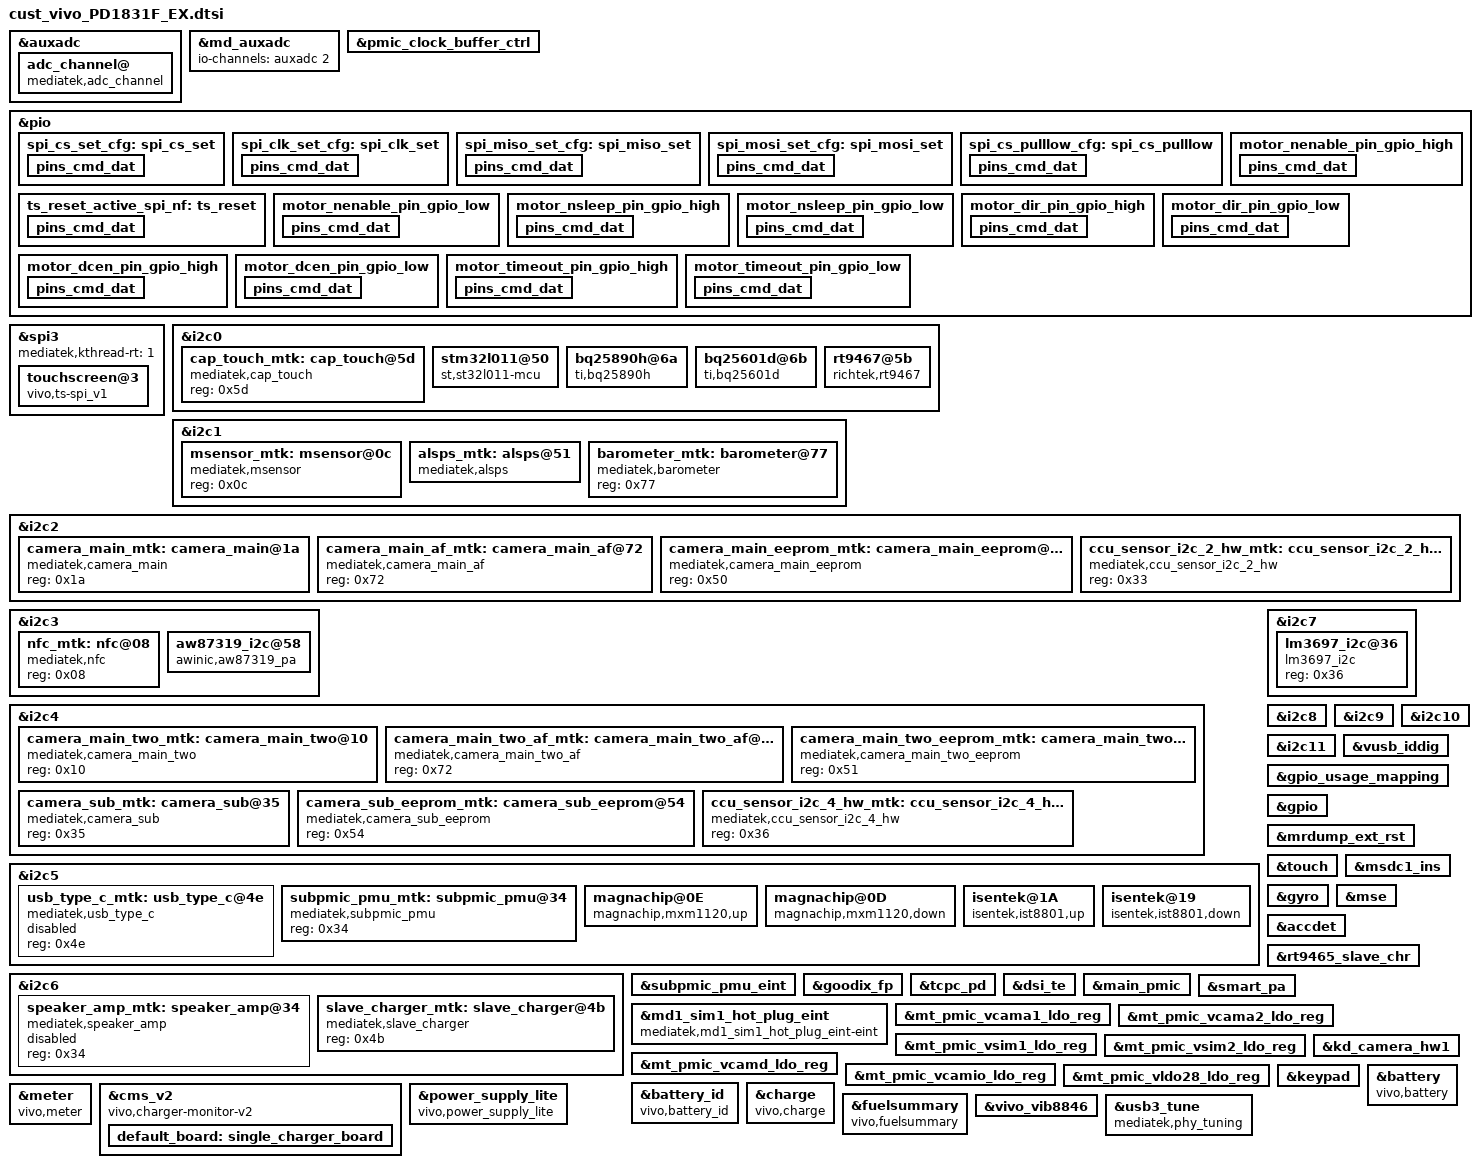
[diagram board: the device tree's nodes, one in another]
/*
 * Generated by MTK SP DrvGen Version: 3.5.160809 for MT6771.
 * 2020-12-16 15:59:14
 * Do Not Modify The File.
 * Copyright Mediatek Inc. (c) 2016.
*/

/*************************
 * ADC DTSI File
*************************/

&auxadc {
	adc_channel@ {
		compatible = "mediatek,adc_channel";
		mediatek,temperature0 = <0>;
		mediatek,temperature1 = <1>;
		mediatek,adc_fdd_rf_params_dynamic_custom_ch = <2>;
		status = "okay";
	};
};
&md_auxadc {
	io-channels = <&auxadc 2>;
};


/*************************
 * CLK_BUF DTSI File
*************************/

&pmic_clock_buffer_ctrl {
	mediatek,clkbuf-quantity = <7>;
	mediatek,clkbuf-config = <2 1 1 2 0 0 1>;
	mediatek,clkbuf-driving-current = <(-1) (-1) (-1) (-1) (-1) (-1) (-1)>;
	status = "okay";
};

&pio {
	spi_cs_set_cfg:spi_cs_set { 
		pins_cmd_dat { 
			pinmux = <PINMUX_GPIO22__FUNC_SPI3_CSB>;			
			drive-strength = <0>; 
		}; 
	}; 
	spi_clk_set_cfg:spi_clk_set { 
		pins_cmd_dat { 
			pinmux = <PINMUX_GPIO24__FUNC_SPI3_CLK>; 
			input-enable; 
			drive-strength = <0>; 
		}; 
	}; 
	spi_miso_set_cfg:spi_miso_set { 
		pins_cmd_dat { 
			pinmux = <PINMUX_GPIO21__FUNC_SPI3_MI>; 
			input-enable; 
			drive-strength = <0>; 
		}; 
	}; 
	spi_mosi_set_cfg:spi_mosi_set { 
		pins_cmd_dat { 
			pinmux = <PINMUX_GPIO23__FUNC_SPI3_MO>; 
			input-enable; 
			drive-strength = <0>; //0:2mA 1:4mA 2:2mA 3:8mA 4:10mA 5:12mA 6:14mA 7:16mA 
		}; 
	}; 
	spi_cs_pulllow_cfg:spi_cs_pulllow {
		pins_cmd_dat {
			pinmux = <PINMUX_GPIO22__FUNC_GPIO22>;
			slew-rate = <1>;
			output-low;
		};
	};
	ts_reset_active_spi_nf: ts_reset {
        pins_cmd_dat {
            pinmux = <PINMUX_GPIO171__FUNC_GPIO171>;
            slew-rate = <0>;
            bias-disable;
            output-low;
        };
    };
}; 

&spi3 {
	#address-cells = <1>;
	#size-cells = <0>;	
	mediatek,kthread-rt = <1>;
	touchscreen@3 {
		compatible = "vivo,ts-spi_v1";
		reg = <0>; //Same as CS ID
		status = "ok";
		
		pinctrl-names = "spi_cs_set", "spi_clk_set", "spi_miso_set", "spi_mosi_set", "spi_cs_pulllow", "ts_reset";
		pinctrl-0 = <&spi_cs_set_cfg>;
		pinctrl-1 = <&spi_clk_set_cfg>;
		pinctrl-2 = <&spi_miso_set_cfg>;
		pinctrl-3 = <&spi_mosi_set_cfg>;
		pinctrl-4 = <&spi_cs_pulllow_cfg>;
		pinctrl-5 = <&ts_reset_active_spi_nf>;
		

		spi-max-frequency = <9600000>;	//4800000,9600000,15000000,19200000
		
		//novatek dtsi
		//novatek,reset-gpio = <&pio 2 0x00>;
		novatek,irq-gpio = <&pio 1 0x02>;
		//novatek,clk-gpio = <&pio 24 0x00>;
		//novatek,cs-gpio = <&pio 22 0x00>;				
		
		//clock-names = "iface_clk", "core_clk";
		//clocks = <&clock_gcc clk_gcc_blsp1_ahb_clk>,
		//	<&clock_gcc clk_gcc_blsp1_qup1_spi_apps_clk>;
		/* 672 */
		//novatek,swrst-n8-addr = <0x01F01A>;

		/* 672A */
		novatek,swrst-n8-addr = <0x03F0FE>;	
		
		//synaptics dtsi
		synaptics,irq-gpio = <&pio 1 0x00>;
		synaptics,spi-mode = <3>;
		synaptics,ubl-max-freq = <6000000>;
		synaptics,ubl-byte-delay-us = <20>;

		synaptics,reset-gpio = <&pio 171 0x00>;
		synaptics,attn_polarity = <0x02>;

		synaptics,power-on-state = <1>;

		synaptics,irq-on-state = <0>;
		//synaptics,power-delay-ms = <200>;
		synaptics,reset-delay-ms = <120>;
		synaptics,reset-on-state = <0>;
		synaptics,reset-active-ms = <1>;

		// FT8719
		focaltech,reset-gpio = <&pio 171 0x00>;
		focaltech,irq-gpio = <&pio 1 0x02>;
		focaltech,max-touch-number = <10>;
		focaltech,display-coords = <0 0 1080 2340>;
		focaltech,spi-max-frequency = <8000000>;
	};	
};


/*************************
 * I2C DTSI File
*************************/

&i2c0 {
	#address-cells = <1>;
	#size-cells = <0>;
	clock-frequency = <400000>;
	mediatek,use-open-drain;
	cap_touch_mtk:cap_touch@5d {
		compatible = "mediatek,cap_touch";
		reg = <0x5d>;
		status = "okay";
	};

};

&i2c1 {
	#address-cells = <1>;
	#size-cells = <0>;
	clock-frequency = <400000>;
	mediatek,use-open-drain;
	msensor_mtk:msensor@0c {
		compatible = "mediatek,msensor";
		reg = <0x0c>;
		status = "okay";
	};

	alsps_mtk:alsps@51 {
		compatible = "mediatek,alsps";
		reg = <0x51>;
		status = "okay";
	};

	barometer_mtk:barometer@77 {
		compatible = "mediatek,barometer";
		reg = <0x77>;
		status = "okay";
	};

};

&i2c2 {
	#address-cells = <1>;
	#size-cells = <0>;
	clock-frequency = <400000>;
	mediatek,use-open-drain;
	camera_main_mtk:camera_main@1a {
		compatible = "mediatek,camera_main";
		reg = <0x1a>;
		status = "okay";
	};

	camera_main_af_mtk:camera_main_af@72 {
		compatible = "mediatek,camera_main_af";
		reg = <0x72>;
		status = "okay";
	};

	camera_main_eeprom_mtk:camera_main_eeprom@50 {
		compatible = "mediatek,camera_main_eeprom";
		reg = <0x50>;
		status = "okay";
	};

	ccu_sensor_i2c_2_hw_mtk:ccu_sensor_i2c_2_hw@33 {
		compatible = "mediatek,ccu_sensor_i2c_2_hw";
		reg = <0x33>;
		status = "okay";
	};

};

&i2c3 {
	#address-cells = <1>;
	#size-cells = <0>;
	clock-frequency = <400000>;
	mediatek,use-open-drain;
	nfc_mtk:nfc@08 {
		compatible = "mediatek,nfc";
		reg = <0x08>;
		status = "okay";
	};

};

&i2c3{
		aw87319_i2c@58 {
			compatible = "awinic,aw87319_pa";
			reg = <0x58>;
			awinic,ext_pa_spk_aw87319_rst = <&pio 153 0>;
		};
};

&i2c4 {
	#address-cells = <1>;
	#size-cells = <0>;
	clock-frequency = <400000>;
	mediatek,use-open-drain;
	camera_main_two_mtk:camera_main_two@10 {
		compatible = "mediatek,camera_main_two";
		reg = <0x10>;
		status = "okay";
	};

	camera_main_two_af_mtk:camera_main_two_af@72 {
		compatible = "mediatek,camera_main_two_af";
		reg = <0x72>;
		status = "okay";
	};

	camera_main_two_eeprom_mtk:camera_main_two_eeprom@51 {
		compatible = "mediatek,camera_main_two_eeprom";
		reg = <0x51>;
		status = "okay";
	};

	camera_sub_mtk:camera_sub@35 {
		compatible = "mediatek,camera_sub";
		reg = <0x35>;
		status = "okay";
	};

	camera_sub_eeprom_mtk:camera_sub_eeprom@54 {
		compatible = "mediatek,camera_sub_eeprom";
		reg = <0x54>;
		status = "okay";
	};

	ccu_sensor_i2c_4_hw_mtk:ccu_sensor_i2c_4_hw@36 {
		compatible = "mediatek,ccu_sensor_i2c_4_hw";
		reg = <0x36>;
		status = "okay";
	};

};

&i2c5 {
	#address-cells = <1>;
	#size-cells = <0>;
	clock-frequency = <400000>;
	mediatek,use-push-pull;
	usb_type_c_mtk:usb_type_c@4e {
		compatible = "mediatek,usb_type_c";
		reg = <0x4e>;
		status = "disable";
	};

	subpmic_pmu_mtk:subpmic_pmu@34 {
		compatible = "mediatek,subpmic_pmu";
		reg = <0x34>;
		status = "okay";
	};

};

&i2c6 {
	#address-cells = <1>;
	#size-cells = <0>;
	clock-frequency = <400000>;
	mediatek,use-open-drain;
	speaker_amp_mtk:speaker_amp@34 {
		compatible = "mediatek,speaker_amp";
		reg = <0x34>;
		status = "disabled";
	};

	slave_charger_mtk:slave_charger@4b {
		compatible = "mediatek,slave_charger";
		reg = <0x4b>;
		status = "okay";
	};

};

&i2c7 {
	#address-cells = <1>;
	#size-cells = <0>;
	clock-frequency = <400000>;
	mediatek,use-open-drain;
	lm3697_i2c@36 {
		compatible = "lm3697_i2c";
		reg = <0x36>;
		status = "okay";
	};

};

&i2c8 {
	#address-cells = <1>;
	#size-cells = <0>;
	clock-frequency = <400000>;
	mediatek,use-open-drain;
};

&i2c9 {
	#address-cells = <1>;
	#size-cells = <0>;
	clock-frequency = <400000>;
	mediatek,use-open-drain;
};

&i2c10 {
	#address-cells = <1>;
	#size-cells = <0>;
	clock-frequency = <400000>;
	mediatek,use-open-drain;
};

&i2c11 {
	#address-cells = <1>;
	#size-cells = <0>;
	clock-frequency = <400000>;
	mediatek,use-open-drain;
};

&vusb_iddig {
	interrupt-parent = <&pio>;
	interrupts = <41 IRQ_TYPE_EDGE_FALLING 41 0>;
	id-gpio = <&pio 41 0>;
	id-debounce = <50>;
	id-pu-debounce = <20>;
	id-pu-times = <5>;
};

/*************************
 * GPIO DTSI File
*************************/

&gpio_usage_mapping {
	GPIO_SIM2_SIO = <&pio 35 0>;
	GPIO_SIM2_SRST = <&pio 36 0>;
	GPIO_SIM2_SCLK = <&pio 37 0>;
	GPIO_SIM1_SCLK = <&pio 38 0>;
	GPIO_SIM1_SRST = <&pio 39 0>;
	GPIO_SIM1_SIO = <&pio 40 0>;
	/*GPIO_SIM2_HOT_PLUG = <&pio 46 0>;*/
	GPIO_SIM1_HOT_PLUG = <&pio 47 0>;
	GPIO_FDD_BAND_SUPPORT_DETECT_1ST_PIN = <&pio 72 0>;
	GPIO_FDD_BAND_SUPPORT_DETECT_2ND_PIN = <&pio 78 0>;
	GPIO_FDD_BAND_SUPPORT_DETECT_3RD_PIN = <&pio 174 0>;
	GPIO_FDD_BAND_SUPPORT_DETECT_4TH_PIN = <&pio 172 0>;
};

&gpio{
	gpio_init_default = <0 0 0 0 1 1 1>,
		<1 0 0 0 1 1 1>,
		<2 0 1 0 0 0 1>,
		<3 0 0 0 1 1 1>,
		<4 0 0 0 1 0 0>,
		<5 0 0 0 1 0 0>,
		<6 0 0 0 1 1 0>,
		<7 0 0 0 1 1 0>,
		<8 7 0 0 1 1 0>,
		<9 0 0 0 1 1 0>,
		<10 0 0 0 1 1 0>,
		<11 3 0 0 1 1 0>,
		<12 3 0 0 1 1 0>,
		<13 2 0 0 1 0 0>,
		<14 2 1 0 0 0 0>,
		<15 2 1 0 1 0 0>,
		<16 2 1 0 0 0 0>,
		<17 0 1 0 1 0 0>,
		<18 0 0 1 1 0 0>,
		<19 0 1 0 0 0 0>,
		<20 0 0 0 1 0 0>,
		<21 2 0 0 1 1 0>,
		<22 2 1 0 0 0 0>,
		<23 2 1 0 0 0 0>,
		<24 2 1 0 0 0 0>,
		<25 5 0 0 1 0 0>,
		<26 5 0 0 1 0 0>,
		<27 3 0 0 0 0 0>,
		<28 3 0 0 0 0 0>,
		<29 1 1 0 0 0 0>,
		<30 1 0 0 1 1 0>,
		<31 1 0 0 1 1 0>,
		<32 1 0 0 1 1 0>,
		<33 1 0 0 1 1 0>,
		<34 1 0 0 1 1 0>,
		<35 1 0 0 1 1 0>,
		<36 1 1 0 0 0 0>,
		<37 1 1 0 0 0 0>,
		<38 1 1 0 0 0 0>,
		<39 1 1 0 0 0 0>,
		<40 1 0 0 1 1 0>,
		<41 0 0 0 1 1 0>,
		<42 0 1 0 0 0 0>,
		<43 1 1 0 0 0 0>,
		<44 1 0 0 1 0 0>,
		<45 0 1 0 0 0 0>,
		<46 0 0 0 0 0 0>,
		<47 1 0 0 0 0 0>,
		<48 1 0 0 1 1 0>,
		<49 1 0 0 1 1 0>,
		<50 1 0 0 1 1 0>,
		<51 1 0 0 1 1 0>,
		<52 1 1 0 1 0 0>,
		<53 1 1 0 1 0 0>,
		<54 1 1 0 1 0 0>,
		<55 1 1 0 1 0 0>,
		<56 1 1 0 1 0 0>,
		<57 1 1 0 1 0 0>,
		<58 0 0 0 1 0 0>,
		<59 1 0 0 1 0 0>,
		<60 1 0 0 1 0 0>,
		<61 1 0 0 1 0 0>,
		<62 1 0 0 1 0 0>,
		<63 1 0 0 1 0 0>,
		<64 1 0 0 1 0 0>,
		<65 1 0 0 1 0 0>,
		<66 1 0 0 1 0 0>,
		<67 1 0 0 1 0 0>,
		<68 1 0 0 1 0 0>,
		<69 1 1 0 1 0 0>,
		<70 1 1 0 1 0 0>,
		<71 1 1 0 1 0 0>,
		<72 0 0 0 1 1 0>,
		<73 1 1 0 1 0 0>,
		<74 1 1 0 1 0 0>,
		<75 1 1 0 1 0 0>,
		<76 1 1 0 1 0 0>,
		<77 1 1 0 1 0 0>,
		<78 0 0 0 1 1 0>,
		<79 1 0 0 1 0 0>,
		<80 1 0 0 1 0 0>,
		<81 1 0 0 1 1 0>,
		<82 1 0 0 1 1 0>,
		<83 1 0 0 1 1 0>,
		<84 1 0 0 1 1 0>,
		<85 7 1 0 0 0 0>,
		<86 7 0 0 1 0 0>,
		<87 7 0 0 1 0 0>,
		<88 7 0 0 1 0 0>,
		<89 1 0 0 1 0 0>,
		<90 0 0 0 1 1 0>,
		<91 0 1 0 0 0 0>,
		<92 1 1 0 1 0 0>,
		<93 1 0 0 1 1 0>,
		<94 1 0 0 1 1 0>,
		<95 1 0 0 1 1 0>,
		<96 1 1 0 0 0 0>,
		<97 0 1 0 0 0 0>,
		<98 0 1 0 0 0 0>,
		<99 0 1 0 0 0 0>,
		<100 0 1 0 0 0 0>,
		<101 0 1 1 0 0 0>,
		<102 0 1 1 0 0 0>,
		<103 1 0 0 0 0 0>,
		<104 1 0 0 0 0 0>,
		<105 1 0 0 0 0 0>,
		<106 1 0 0 0 0 0>,
		<107 0 1 0 0 0 0>,
		<108 0 1 0 0 0 0>,
		<109 0 1 1 0 0 0>,
		<110 7 0 0 1 1 0>,
		<111 0 0 0 0 0 0>,
		<112 7 1 0 0 0 0>,
		<113 0 0 0 1 0 0>,
		<114 0 0 0 1 0 0>,
		<115 0 0 0 1 0 0>,
		<116 0 0 0 1 0 0>,
		<117 0 0 0 1 0 0>,
		<118 0 0 0 1 0 0>,
		<119 0 0 0 1 0 0>,
		<120 0 0 0 1 0 0>,
		<121 0 0 0 1 0 0>,
		<122 1 0 0 1 1 0>,
		<123 1 0 0 1 1 0>,
		<124 1 1 0 0 0 0>,
		<125 1 0 0 1 1 0>,
		<126 1 0 0 1 1 0>,
		<127 1 0 0 1 1 0>,
		<128 1 0 0 1 1 0>,
		<129 1 0 0 1 1 0>,
		<130 1 0 0 1 1 0>,
		<131 1 0 0 1 0 0>,
		<132 1 0 0 1 1 0>,
		<133 1 1 1 0 0 0>,
		<134 1 0 0 1 0 1>,
		<135 1 1 0 0 0 0>,
		<136 1 1 0 1 0 0>,
		<137 1 1 0 1 0 0>,
		<138 1 1 0 0 0 0>,
		<139 1 1 0 1 0 0>,
		<140 1 0 0 0 0 0>,
		<141 1 0 0 0 0 0>,
		<142 1 0 0 0 0 0>,
		<143 1 0 0 0 0 0>,
		<144 1 0 0 1 0 0>,
		<145 1 1 1 0 0 0>,
		<146 1 0 0 1 0 0>,
		<147 1 1 0 0 0 0>,
		<148 1 1 0 0 0 0>,
		<149 1 1 0 0 0 0>,
		<150 0 1 0 0 0 0>,
		<151 0 1 0 0 0 0>,
		<152 0 1 0 0 0 0>,
		<153 0 1 0 0 0 0>,
		<154 1 1 0 0 0 0>,
		<155 1 0 0 1 0 0>,
		<156 4 0 0 1 1 0>,
		<157 0 0 0 1 0 0>,
		<158 0 0 0 1 1 0>,
		<159 0 0 0 1 1 0>,
		<160 0 0 0 1 1 0>,
		<161 2 0 0 1 0 0>,
		<162 2 1 1 0 0 0>,
		<163 2 1 0 0 0 0>,
		<164 2 1 0 0 0 0>,
		<165 1 1 1 0 0 0>,
		<166 0 1 0 0 0 0>,
		<167 1 1 0 1 0 0>,
		<168 1 1 0 1 0 0>,
		<169 0 1 0 0 0 0>,
		<170 3 0 0 0 0 0>,
		<171 0 1 0 0 0 0>,
		<172 0 0 0 1 1 0>,
		<173 0 0 0 1 1 0>,
		<174 0 0 0 1 1 0>,
		<175 0 0 0 1 0 0>,
		<176 0 0 0 1 0 0>,
		<177 0 1 0 0 0 0>,
		<178 0 0 0 1 0 0>,
		<179 0 1 0 0 0 0>,
		<180 0 0 0 1 0 0>,
		<181 0 0 0 1 0 0>,
		<182 0 0 0 1 0 0>,
		<183 0 0 0 1 0 0>,
		<184 0 0 0 1 0 0>,
		<185 0 0 0 1 0 0>,
		<186 0 0 0 1 0 0>,
		<187 0 0 0 1 0 0>,
		<188 0 0 0 1 0 0>,
		<189 0 0 0 1 0 0>,
		<190 0 0 0 1 0 0>,
		<191 0 0 0 1 0 0>;
};


/*************************
 * EINT DTSI File
*************************/

#include <dt-bindings/interrupt-controller/irq.h>
#include <dt-bindings/interrupt-controller/arm-gic.h>

&mrdump_ext_rst {
	interrupt-parent = <&pio>;
	interrupts = <0 IRQ_TYPE_LEVEL_LOW 0 0>;
	deb-gpios = <&pio 0 0>;
	debounce = <512000>;
	status = "okay";
};

&touch {
	interrupt-parent = <&pio>;
	interrupts = <1 IRQ_TYPE_EDGE_FALLING 1 0>;
	status = "okay";
};

&msdc1_ins {
	interrupt-parent = <&pio>;
	interrupts = <3 IRQ_TYPE_LEVEL_LOW 3 0>;
	deb-gpios = <&pio 3 0>;
	debounce = <256000>;
	status = "okay";
};

&gyro {
	interrupt-parent = <&pio>;
	interrupts = <4 IRQ_TYPE_LEVEL_LOW 4 0>;
	status = "okay";
};

&mse {
	interrupt-parent = <&pio>;
	interrupts = <5 IRQ_TYPE_LEVEL_HIGH 5 0>;
	status = "okay";
};

&alsps_mtk {
	interrupt-parent = <&pio>;
	interrupts = <6 IRQ_TYPE_LEVEL_LOW 6 0>;
	status = "okay";
};

&accdet {
	interrupt-parent = <&pio>;
	interrupts = <8 IRQ_TYPE_LEVEL_LOW 8 0>;
	deb-gpios = <&pio 8 0>;
	debounce = <256000>;
	status = "okay";
};

&rt9465_slave_chr {
	interrupt-parent = <&pio>;
	interrupts = <9 IRQ_TYPE_LEVEL_LOW 9 0>;
	status = "okay";
};

&subpmic_pmu_eint {
	interrupt-parent = <&pio>;
	interrupts = <10 IRQ_TYPE_LEVEL_LOW 10 0>;
	status = "okay";
};

&goodix_fp {
	interrupt-parent = <&pio>;
	interrupts = <5 IRQ_TYPE_EDGE_RISING 5 0>;
	status = "okay";
};

&tcpc_pd {
	interrupt-parent = <&pio>;
	interrupts = <41 IRQ_TYPE_LEVEL_LOW 41 0>;
	status = "okay";
};

&dsi_te {
	interrupt-parent = <&pio>;
	interrupts = <44 IRQ_TYPE_EDGE_RISING 44 1>;
	status = "okay";
};

&main_pmic {
	interrupt-parent = <&pio>;
	interrupts = <182 IRQ_TYPE_LEVEL_HIGH 190 0>;
	status = "okay";
};

&smart_pa {
	interrupt-parent = <&pio>;
	interrupts = <186 IRQ_TYPE_LEVEL_LOW 173 0>;
	status = "okay";
};



/*************************
 * MD1_EINT DTSI File
*************************/

&md1_sim1_hot_plug_eint {
	compatible = "mediatek,md1_sim1_hot_plug_eint-eint";
	interrupts = <0 8>;
	debounce = <0 100000>;
	dedicated = <0 0>;
	src_pin = <0 1>;
	sockettype = <0 0>;
	status = "okay";
};

/*
&md1_sim2_hot_plug_eint {
	compatible = "mediatek,md1_sim2_hot_plug_eint-eint";
	interrupts = <1 4>;
	debounce = <1 100000>;
	dedicated = <1 0>;
	src_pin = <1 2>;
	sockettype = <1 0>;
	status = "okay";
};
*/


/*************************
 * PMIC DTSI File
*************************/

&mt_pmic_vcama1_ldo_reg {
	regulator-name = "vcama1";
	regulator-default-on = <1>; /* 0:skip, 1: off, 2:on */
	status = "okay";
};
&mt_pmic_vcama2_ldo_reg {
	regulator-name = "vcama2";
	regulator-default-on = <1>; /* 0:skip, 1: off, 2:on */
	status = "okay";
};
&mt_pmic_vsim1_ldo_reg {
	regulator-name = "vsim1";
	regulator-default-on = <1>; /* 0:skip, 1: off, 2:on */
	status = "okay";
};
&mt_pmic_vsim2_ldo_reg {
	regulator-name = "vsim2";
	regulator-default-on = <1>; /* 0:skip, 1: off, 2:on */
	status = "okay";
};
&mt_pmic_vcamd_ldo_reg {
	regulator-name = "vcamd";
	regulator-default-on = <1>; /* 0:skip, 1: off, 2:on */
	status = "okay";
};
&mt_pmic_vcamio_ldo_reg {
	regulator-name = "vcamio";
	regulator-default-on = <1>; /* 0:skip, 1: off, 2:on */
	status = "okay";
};
&mt_pmic_vldo28_ldo_reg {
	regulator-name = "vldo28";
	regulator-default-on = <1>; /* 0:skip, 1: off, 2:on */
	status = "okay";
};

&kd_camera_hw1 {
	vcama_sub-supply = <&mt_pmic_vcama1_ldo_reg>;
	vcama-supply = <&mt_pmic_vcama2_ldo_reg>;
	vcamd_sub-supply = <&mt_pmic_vcamd_ldo_reg>;
	vcamio-supply = <&mt_pmic_vcamio_ldo_reg>;
	vcamio_sub-supply = <&mt_pmic_vcamio_ldo_reg>;
	vcamio_main2-supply = <&mt_pmic_vcamio_ldo_reg>;
	vcamaf-supply = <&mt_pmic_vldo28_ldo_reg>;
	vcamaf_sub-supply = <&mt_pmic_vldo28_ldo_reg>;
	vcamaf_main2-supply = <&mt_pmic_vldo28_ldo_reg>;
	status = "okay";
};

&touch {
	vtouch-supply = <&mt_pmic_vldo28_ldo_reg>;
	status = "okay";
};


/*************************
 * POWER DTSI File
*************************/



/*************************
 * KPD DTSI File
*************************/

&keypad {
	mediatek,kpd-key-debounce = <1024>;
	mediatek,kpd-sw-pwrkey = <116>;
	mediatek,kpd-hw-pwrkey = <8>;
	mediatek,kpd-sw-rstkey  = <114>;
	mediatek,kpd-hw-rstkey = <17>;
	mediatek,kpd-use-extend-type = <0>;
	/*HW Keycode [0~71] -> Linux Keycode*/
	mediatek,kpd-hw-map-num = <72>;
	mediatek,kpd-hw-init-map = <115 0 600 0 0 0 0 0 0 0 0 0 0 0 0 0 0 0 0 0 0 0 0 0 0 0 0 0 0 0 0 0 0 0 0 0 0 0 0 0 0 0 0 0 0 0 0 0 0 0 0 0 0 0 0 0 0 0 0 0 0 0 0 0 0 0 0 0 0 0 0 0 >;
	mediatek,kpd-pwrkey-eint-gpio = <0>;
	mediatek,kpd-pwkey-gpio-din  = <0>;
	mediatek,kpd-hw-dl-key0 = <17>;
	mediatek,kpd-hw-dl-key1 = <0>;
	mediatek,kpd-hw-dl-key2 = <8>;
	mediatek,kpd-hw-recovery-key = <17>;
	mediatek,kpd-hw-factory-key = <0>;
	status = "okay";
};

/* fuxi add for battery&charge start */
&battery_id {
	status = "okay";
	compatible = "vivo,battery_id";

	vivo,bat-adc-ctrl-gpio = <&pio 166 0>;

	io-channels = <&auxadc 3>;
	io-channel-names = "battery_id_adc";

	vivo,bat-name = "B-G2 ATL 4000","B-G6 ATL 3940","B-G2 SX 4000","B-G2 ATL 4000", "UNKOWN", "UNKOWN";
};

&battery {
	status = "okay";
	compatible = "vivo,battery";

	io-channels = <&auxadc 0>,
		<&auxadc 1>,
		<&auxadc 2>;
	io-channel-names = "primary_board_therm",
		"pa_therm",
		"parallel_board_therm";

	vivo,low-volt-threshold = <3400>;
	vivo,soft-rise-percent = <92>;
	vivo,soft-rise-cumulative = <10>;
	vivo,soft-rise-keep-cumulative = <14>;
	vivo,percnet-sync-delta = <4>;
	vivo,percnet-sync-cumulative = <9>;
	vivo,full-sync-cumulative = <3>;
	vivo,soft-term-percent = <99>;
	vivo,soft-term-cumulative = <48>;
};

&charge {
	status = "okay";
	compatible = "vivo,charge";

	vivo,chg-wdt-s = <40>;
	vivo,re-chg-voltage-mv = <100>;
	vivo,prechg-voltage-mv = <3000>;
	vivo,iprechg-current-ma = <300>;
	vivo,iterm-current-ma = <256>;
	vivo,vreg-voltage-mv = <4430>;
	vivo,vindpm-voltage-mv = <4600>;
	vivo,sys-voltage-min-mv= <3300>;
	vivo,boostv-voltage-mv = <5150>;
	vivo,boostv-ilimit-ma = <1500>;
	vivo,ovp-voltage-mv = <15000>;

	vivo,battery-id-vreg-mv = <4430 4430 4430 4430 4430 4430>;
	/*
	 * 0  auto detect charging
	 * 1  vivo-normal chargine
	 * 2  vivo-single engine charging
	 * 3  vivo-dual engine charging
	 * 4  vivo-flash charging
	*/
	vivo,charge-scheme = <0>;
	vivo,direct-charger-enable;

	/*
	 * SUPPORTED_ADAPTER_DEFAULT = 0,
	 * SUPPORTED_ADAPTER_VIVO_LV_DCHG_5V_4500MA = 1,
	 * SUPPORTED_ADAPTER_VIVO_HV_DCHG_10V_2250MA = 2,
	 * SUPPORTED_ADAPTER_QC20__9V_2000MA = 3,
	 * SUPPORTED_ADAPTER_VIVO_HV_DCHG_10V_4000MA = 4,
	 * SUPPORTED_ADAPTER_MAX,
	 */
	vivo,supported-adapter = <3>;

	//parameter for 9V2A
	vivo,primary-ichg-max-ma = <2240>;
	vivo,parallel-ichg-max-ma = <1740>;

	vivo,flashchg-spec-ma = <2000 3300 6000>;
	vivo,fastchg-spec-ma = <2000 2100 3800>;
	vivo,normalchg-spec-ma = <2000 1500 2300>;

	/* 0---PMIC; 1---CHGIC */
	vivo,vbus-detect-source = <1>;

	vivo,usboe-gpio = <&pio 25 0>;

	/*ffc*/
	//vivo,ffc-enable;
	vivo,ffc-iterm-ma = <(-750)>;
	vivo,ffc-vreg-mv = <4500>;
	vivo,ffc-temperature-range = <150 450>;
	vivo,ffc-full-vbat-table-size = <3>;
	vivo,ffc-full-vbat-table = <4480 4490 4460>;
	vivo,ffc-full-ibat-table-size = <2>;
	vivo,ffc-full-ibat-table = <150 349 (-980)>,
		<350 449 (-1176)>;
};

&meter {
	status = "okay";
	compatible = "vivo,meter";

	vivo,load-capacity-delta-max = <60>;
	vivo,poweron-delta-capacity = <20>;
	vivo,poweron-low-capacity = <3>;
	vivo,volt-car-delta = <8>;
	vivo,car-volt-delta = <6>;
	vivo,meter-res-compesate = <10>;
	vivo,ocv-board-compesate = <0>;

	/* 0---AGING_UNSUPPORTED; 1---DRIVER_SUPPORTED; 2---USPACE_SUPPORTED */
	vivo,battery-aging-support = <2>;

	vivo,capacity-mAh = <4910>;
	/*COLD_CHG COLD_DISCHG NORMAL_CHG NORMAL_DISCHG*/
	vivo,car-tune-value = <1045 1000 1045 1000>,
		<1045 1000 1045 1000>,
		<1045 1000 1045 1000>,
		<1045 1000 1045 1000>,
		<1045 1000 1045 1000>,
		<1045 1000 1045 1000>;
	vivo,bats-qmax = <3600 3677 3800 3873 3862>,
		<3600 3677 3800 3873 3862>,
		<3600 3677 3800 3873 3862>,
		<3600 3677 3800 3873 3862>,
		<3600 3677 3800 3873 3862>,
		<3600 3677 3800 3873 3862>;

	/* car-tune adjust remap */
	vivo,car-tune-adjust-enable;
	vivo,car-tune-adjust-size = <3>;
	vivo,car-tune-adjust-table = <0 10 (360) 6>,
		<11 20 (-35) 7>,
		<21 100 (-45) 8>;

	#include "bat_setting/PD1831_battery_table.dtsi"
};

&cms_v2 {
	compatible = "vivo,charger-monitor-v2";
	status = "okay";

	default_board: single_charger_board {
		/*default board: keep in xxxxxx*/
		support-board-version = "xxxxxx";

		vivo,bat-det-method = <0>;//r:0, rc:1, eprom:2, ex-fg:3
		//vivo,bat-id-gpio = <&pio 158 0>;

		//vivo,no-bat-warning;
		//vivo,no-chg-timeout;
		vivo,chg-timeout-mins = <900>;

		//high temperature charger current control enable
		vivo,htccc-enable;
		vivo,htccc-data = <46 55 4100000 100000>;

		//vivo,fbon-scale-enable;/*disable default*/
		vivo,fbon-scale-data = <2 100 100>;

		//vivo,switch-scale-enable;/*disable from rom4.0*/
		vivo,switch-scale-data = <75 53>;

		vivo,calling-scale-enable;
		vivo,calling-scale-data = <100 21>;/*ibat:3900 * 0.54 = 2106,more than 1500,not exit dchg*/
		vivo,calling-dchg-disable;

		vivo,weixin-calling-scale-enable;
		vivo,weixin-calling-scale-data = <100 112>;/*5000mA*/

		//vivo,fixed-scale-enable;
		vivo,fixed-scale-data = <120 3800 0>;/*dchg fixed time adjust the max ibat,disable default*/

		/*data processing : batt-temp*/
		vivo,dp-batt-temp-enable;
		vivo,dp-batt-temp-data = <100>;

		/* charging current for devices in exhibition mode */
		vivo,exhibition-mode-current-primary = <2048>;
		vivo,exhibition-mode-current-parallel = <0>;

		/*default tc parameter*/
		//single charger ibat scale base on temperature battery cell info:1C/1.2C 3960mah
		/* tmin, tmax, data, volt1, data_ex1, volt2, data_ex2. */
		vivo,normal-tc-row-col = <10 7>;
		vivo,normal-tc-data = <550 8888 0 0 0 0 0>,
			<450 549 50 0 0 0 0>,
			<200 449 100 4200000 70 0 0>,
			<150 199 70 0 0 0 0>,
			<100 149 70 4200000 50 0 0>,
			<50 99 30 0 0 0 0>,
			<0 49 30 0 0 0 0>,
			<(-8888) (-1) 0 0 0 0 0>,
			<(-8888) (-1) 0 0 0 0 0>,
			<(-8888) (-1) 0 0 0 0 0>;

		/*flash tc parameter*/
		vivo,flash-normal-tc-row-col = <10 7>;
		vivo,flash-normal-tc-data = <550 8888 0 0 0 0 0>,
			<450 549 50 0 0 0 0>,
			<200 449 223 4390000 179 4400000 134>,
			<150 199 203 4250000 152 0 0>,
			<100 149 120 4200000 100 0 0>,
			<50 99 70 4200000 50 0 0>,
			<0 49 50 4380000 50 0 0>,
			<(-50) (-1) 30 0 0 0 0>,
			<(-100) (-51) 20 0 0 0 0>,
			<(-8888) (-101) 0 0 0 0 0>;

		/*adjust fastchg base on board temperature and fb off*/
		vivo,intell-charge-enable;
		vivo,parallel-temp-enable = <1 1>;//<x y> x:fb-on y:fb-off

		/* Flash charge fb-on intell param */
		vivo,primary-fbon-tc-row-col = <6 3>;
		vivo,primary-fbon-tc-data = <460 8888 1600>,
			<410 459 2600>,
			<400 409 3000>,
			<390 399 3300>,
			<371 389 3700>,
			<(-8888) 370 6000>;

		vivo,parallel-fbon-tc-row-col = <1 3>;
		vivo,parallel-fbon-tc-data = <(-8888) 8888 0>;


		/* Flash charge fb-off intell param */
		vivo,primary-fboff-tc-row-col = <6 3>;
		vivo,primary-fboff-tc-data = <450 8888 1800>,
			<390 449 3000>,
			<380 389 3400>,
			<376 379 3700>,
			<371 375 4100>,
			<(-8888) 370 6000>;
		vivo,parallel-fboff-tc-row-col = <1 3>;
		vivo,parallel-fboff-tc-data = <(-8888) 8888 0>;


		/* 9v Fast charge fb-on intell param */
		vivo,9v-primary-fbon-tc-row-col = <7 3>;
		vivo,9v-primary-fbon-tc-data = <491 8888 512>,
			<471 490 750>,
			<451 470 900>,
			<431 450 1300>,
			<411 430 1400>,
			<381 410 1500>,
			<(-8888) 380 1600>;
		vivo,9v-parallel-fbon-tc-row-col = <6 3>;
		vivo,9v-parallel-fbon-tc-data = <451 8888 512>,
			<431 450 800>,
			<401 430 1000>,
			<391 400 1100>,
			<371 390 1300>,
			<(-8888) 370 1500>;
		// second parallel parameter, for rt9467
		vivo,9v-2nd-parallel-fbon-tc-row-col = <6 3>;
		vivo,9v-2nd-parallel-fbon-tc-data = <451 8888 512>,
			<431 450 800>,
			<401 430 1000>,
			<391 400 1100>,
			<371 390 1300>,
			<(-8888) 370 1500>;

		/* 9v Fast charge fb-off intell param */
		vivo,9v-primary-fboff-tc-row-col = <7 3>;
		vivo,9v-primary-fboff-tc-data = <451 8888 700>,
			<431 450 1024>,
			<411 430 1200>,
			<391 410 1500>,
			<371 390 1700>,
			<361 370 1800>,
			<(-8888) 360 2048>;
		vivo,9v-parallel-fboff-tc-row-col = <7 3>;
		vivo,9v-parallel-fboff-tc-data = <441 8888 750>,
			<431 440 1050>,
			<406 430 1150>,
			<391 405 1350>,
			<376 390 1450>,
			<361 375 1550>,
			<(-8888) 360 1700>;
		// second parallel parameter, for rt9467
		vivo,9v-2nd-parallel-fboff-tc-row-col = <7 3>;
		vivo,9v-2nd-parallel-fboff-tc-data = <441 8888 700>,
			<431 440 1000>,
			<406 430 1100>,
			<391 405 1300>,
			<376 390 1400>,
			<361 375 1500>,
			<(-8888) 360 1700>;


		/* 5v Normal charge fb-on intell param */
		vivo,5v-primary-fbon-tc-row-col = <7 3>;
		vivo,5v-primary-fbon-tc-data = <486 8888 512>,
			<476 485 700>,
			<461 475 1000>,
			<431 460 1408>,
			<411 430 1600>,
			<381 410 1800>,
			<(-8888) 380 2048>;
		vivo,5v-parallel-fbon-tc-row-col = <1 3>;
		vivo,5v-parallel-fbon-tc-data = <(-8888) 8888 0>;

		/* 5v Normal charge fb-off intell param */
		vivo,5v-primary-fboff-tc-row-col = <6 3>;
		vivo,5v-primary-fboff-tc-data = <491 8888 512>,
			<471 490 1024>,
			<451 470 1216>,
			<431 450 1600>,
			<411 430 1800>,
			<(-8888) 410 2048>;
		vivo,5v-parallel-fboff-tc-row-col = <1 3>;
		vivo,5v-parallel-fboff-tc-data = <(-8888) 8888 0>;

		// Direct charging param
		vivo,direct-charger-enable;//porting_check
		vivo,ex-bms-psy-name = "bq_bms";

		// bat_baord, usb_conn, pcb_conn(master_bat_conn), bat_conn
		vivo,dchg-ntc-protect-enable;
		vivo,dchg-ntc-protect-data = <750 800 850 850>;

		vivo,adapter-cooldown-data = <900 850 3400>;
		/*adapter power derate*/
		vivo,adapter-power-derate-enable;

		/* usb connecter protect param
		 * USB_PROTECT_NONE = 0,
		 * USB_CONN_TEMP_HEAT_PROTECT = BIT(0),
		 * USB_ID_PROTECT = BIT(1),
		 */
		vivo,usb-connecter-protect-enable = <1>;
		vivo,usb-id-protect-data= <1100 1547 500>;/* 500K, 2M, fcc */
		vivo,usb-conn-heat-protect-data-row-col = <2 4>;
		vivo,usb-conn-heat-protect-data= <260 8888 670 620>,
			<(-8888) 259 570 520>;

		/* usb conn protect function */
		//vivo,usb-conn-pro-enable;
		//vivo,usb-conn-pro-gpio = <&pio 159 0>;

		/*
		 * max vbus of adapter:11v, max ibus of adapter:5A
		 * min voltage of battery for half chg:3500mV,max voltage of battery for half charge:4100mV,
		 * 5V2A charge min current threshold: 1000mA,5V2A charge max current threshold:2100mA,
		 * flash charge min current threshold:5000mA,flash charge max current threshold:11000mA
		 */

		/*default parameter*/
		vivo,charge-param-judge-threshold = <9 2 3500 4300 1000 2100 2100 4600>;
		/* factory mode charging test param */
		vivo,charge-test-param-row-col = <12 3>;
		vivo,charge-test-param-data = <0 0 5500>, /* cable resistance, min value, max value */
		        <0 0 5500>, /* master ibus, min ibus, max ibus */
		        <0 0 5500>, /* slave ibus, min ibus, max ibus */
		        <1 20 40>, /* batt therm ntc, min value, max value */
		        <1 20 45>, /* board therm ntc, min value, max value */
		        <0 20 50>, /* sub charger ntc, min value, max value */
		        <0 20 45>, /* usb con ntc, min value, max value */
		        <0 20 45>, /* usb con 1 ntc, double usb NTC, min value, max value */
		        <0 20 45>, /* bat btb master ntc, min value, max value */
		        <0 20 50>, /* bat btb sub ntc, min value, max value */
		        <0 20 50>, /* bat board ntc, min value, max value */
		        <0 20 50>; /* wireless charge coil ntc, min value, max value */

		/*flash parameter*/
		vivo,flash-charge-param-judge-threshold = <11 3 3500 4100 1000 2200 4000 6100>;
		/* factory mode charging test param */
		vivo,flash-charge-test-param-row-col = <12 3>;
		vivo,flash-charge-test-param-data = <1 0 5500>, /* cable resistance, min value, max value */
		        <1 0 5500>, /* master ibus, min ibus, max ibus */
		        <0 0 5500>, /* slave ibus, min ibus, max ibus */
		        <1 20 40>, /* batt therm ntc, min value, max value */
		        <1 20 45>, /* board therm ntc, min value, max value */
		        <0 20 50>, /* sub charger ntc, min value, max value */
		        <1 20 45>, /* usb con ntc, min value, max value */
		        <0 20 45>, /* usb con 1 ntc, double usb NTC, min value, max value */
		        <1 20 45>, /* bat btb master ntc, min value, max value */
		        <0 20 50>, /* bat btb sub ntc, min value, max value */
		        <0 20 50>, /* bat board ntc, min value, max value */
		        <0 20 50>; /* wireless charge coil ntc, min value, max value */
	};
};

&power_supply_lite {
	status = "okay";
	compatible = "vivo,power_supply_lite";
};

&fuelsummary {
	status = "okay";
	compatible = "vivo,fuelsummary";

	/************************************************************
	 *
	 *  0   vivo-fastchg
	 *  1   qcom-dualchg
	 *  2   mtk-dualchg
	 *  3   qcom-normchg
	 *  4   mtk-normchg
	 *
	 ***********************************************************/
	chg-scheme = <2>;
	fex-version = <3>;
	fbon-ibat = <(-900)>;
	fboff-ibat = <(-1000)>;

	/* 0---AGING_UNSUPPORTED; 1---DRIVER_SUPPORTED; 2---USPACE_SUPPORTED */
	vivo,battery-aging-support = <2>;
};

&i2c0 {
	#address-cells = <1>;
	#size-cells = <0>;
	status = "okay";
	clock-frequency = <100000>;

	stm32l011@50 {
		compatible = "st,st32l011-mcu";
		reg = <0x50>;

		//vpower-ldo-supply = <&mt_pmic_vcn33_2_wifi_ldo_reg>;
		//vivo,power-gpio = <&pio 27 0>;//ZC_LDO_EN
		//vivo,int-gpio = <&pio 6 0>;//MCU_INT_AP
		//vivo,usbsel-gpio = <&pio 13 0>;//USB_SW_EN
		//vivo,shift-en-gpio = <&pio 12 0>;//SHIFT_EN
		//vivo,chg-version-gpio = <&pio 64 0>;//°æ±¾Ê¶±ð
		//vivo,sbu-pwr-gpio = <&pio 20 0>;
		ti,temp-cold-degc = <2>;
		ti,temp-hot-degc = <43>;
		vivo,total-limit-max-ma = <6000>;
		vivo,bigdata-collect-time-limit = <95>;//seconds
		vivo,direct-charger-enable;//porting_check

		/*FFC charge: */
		vivo,ffc-support;
		vivo,ffc-temperature-range = <150 450>;
		//vivo,ffc-param-tuning-enable = <1963>;
		vivo,ffc-cc-to-cv-ibat-thr-rc = <1 3>;
		/*<Tmin Tmax current>*/
		vivo,ffc-cc-to-cv-ibat-thr-table = <150 450 4900>;
		vivo,ffc-dchg-cv-mv-rc = <3 2>;
		/*btb_cv,fg_cv*/
		vivo,ffc-dchg-cv-mv-table = <4450 4430>,/*default*/
			<4500 4480>,/*single_charging*/
			<4500 4480>;/*dual_charging*/

		//vivo,cout-int-gpio = <&pio 5 0>;

		vivo,sbu-cable-id-detect-enable;

		vivo,bat-board-temp-enable = <0>;
		vivo,usb-conn-temp-enable = <1>;
		vivo,bat-conn-temp-enable = <1>;

		vivo,master-bat-conn-temp-enable = <2>;
		vivo,dchg-exit-ntc-threshold = <700 650 700 700 1200>;

		/* BQ25970_SINGLE_DCHG:
		 * DCHG_SINGLE_TYPE_22P5W = 0,
		 * DCHG_SINGLE_TYPE_33W = 1,
		 * DCHG_SINGLE_TYPE_44W = 2,
		 * BQ25970_DUAL_DCHG:DCHG_DUAL_TYPE_44W = 3,
		 */
		vivo,dchg-supported-type = <1>;
		/*adapter power derate*/
		vivo,adapter-power-derate-enable;

		//vivo,single-charger-enable;
		vivo,adapter-sha-encryption;

		io-channels = <&auxadc 4>,
			<&auxadc 5>;

		io-channel-names = "sbu2_cable_id_adc",
			"sbu1_cable_id_adc";

		/*cable r limit table :
		  <rmin,rmax, dchg_ibus_max, cable_id_type, limit_count>
		  cable_id_type: 0:effective cable id, 1:other(default) cable id
		 */
		vivo,cable-r-limit-table-rc = <9 5>;
		vivo,cable-r-limit-table = <(-8888) 271 4000 0 0>,
			<272 329 3000 0 0>,
			<330 394 2250 0 0>,
			<395 505 1800 0 0>,
			<506 8888 0 0 0>,
			<(-8888) 329 3000 1 0>,
			<330 394 2250 1 0>,
			<395 505 1800 1 0>,
			<506 8888 0 1 0>;

		/*load firmware profile*/
		vivo,fw-id-range-pct = <100>;
		#include "bat_setting/mcu-firmware-data-33w.dtsi"
		#include "bat_setting/mcu-firmware-data-44w.dtsi"
	};

	bq25890h@6a {
		compatible = "ti,bq25890h";
		reg = <0x6a>;

		vivo,int-gpio = <&pio 10 0>;
	};

	bq25601d@6b {
		compatible = "ti,bq25601d";
		reg = <0x6b>;

		vivo,int-gpio = <&pio 2 0>;
		vivo,enable-gpio = <&pio 160 0>;
	};

	rt9467@5b {
		compatible = "richtek,rt9467";
		reg = <0x5b>;

		//vivo,int-gpio = <&pio 10 0>;//main ic second

		vivo,int-gpio = <&pio 2 0>;
		vivo,enable-gpio = <&pio 160 0>;
	};
};
/* fuxi add for battery&charge end */

/* Add by vsen team [vivo vib camera] */
&pio {
	motor_nenable_pin_gpio_high: motor_nenable_pin_gpio_high{
		pins_cmd_dat {
			pinmux = <PINMUX_GPIO176__FUNC_GPIO176>;
			slew-rate = <1>;
			output-high;
		};
	};
	motor_nenable_pin_gpio_low: motor_nenable_pin_gpio_low{
		pins_cmd_dat {
			pinmux = <PINMUX_GPIO176__FUNC_GPIO176>;
			slew-rate = <1>;
			output-low;
		};
	};

	motor_nsleep_pin_gpio_high: motor_nsleep_pin_gpio_high{
		pins_cmd_dat {
			pinmux = <PINMUX_GPIO17__FUNC_GPIO17>;
			slew-rate = <1>;
			output-high;
		};
	};
	motor_nsleep_pin_gpio_low: motor_nsleep_pin_gpio_low{
		pins_cmd_dat {
			pinmux = <PINMUX_GPIO17__FUNC_GPIO17>;
			slew-rate = <1>;
			output-low;
		};
	};

	motor_dir_pin_gpio_high: motor_dir_pin_gpio_high{
		pins_cmd_dat {
			pinmux = <PINMUX_GPIO175__FUNC_GPIO175>;
			slew-rate = <1>;
			output-high;
		};
	};
	motor_dir_pin_gpio_low: motor_dir_pin_gpio_low{
		pins_cmd_dat {
			pinmux = <PINMUX_GPIO175__FUNC_GPIO175>;
			slew-rate = <1>;
			output-low;
		};
	};

	motor_dcen_pin_gpio_high: motor_dcen_pin_gpio_high{
		pins_cmd_dat {
			pinmux = <PINMUX_GPIO18__FUNC_GPIO18>;
			slew-rate = <1>;
			output-high;
		};
	};
	motor_dcen_pin_gpio_low: motor_dcen_pin_gpio_low{
		pins_cmd_dat {
			pinmux = <PINMUX_GPIO18__FUNC_GPIO18>;
			slew-rate = <1>;
			output-low;
		};
	};

	motor_timeout_pin_gpio_high: motor_timeout_pin_gpio_high{
		pins_cmd_dat {
			pinmux = <PINMUX_GPIO170__FUNC_GPIO170>;
			slew-rate = <1>;
			output-high;
		};
	};
	motor_timeout_pin_gpio_low: motor_timeout_pin_gpio_low{
		pins_cmd_dat {
			pinmux = <PINMUX_GPIO170__FUNC_GPIO170>;
			slew-rate = <1>;
			output-low;
		};
	};
};

&vivo_vib8846 {
	pinctrl-names = "motor_nenable_pin_gpio_high","motor_nenable_pin_gpio_low","motor_nsleep_pin_gpio_high",
			"motor_nsleep_pin_gpio_low","motor_dir_pin_gpio_high","motor_dir_pin_gpio_low","motor_dcen_pin_gpio_high",
			"motor_dcen_pin_gpio_low","motor_timeout_pin_gpio_high","motor_timeout_pin_gpio_low";
	pinctrl-0 = <&motor_nenable_pin_gpio_high>;
	pinctrl-1 = <&motor_nenable_pin_gpio_low>;
	pinctrl-2 = <&motor_nsleep_pin_gpio_high>;
	pinctrl-3 = <&motor_nsleep_pin_gpio_low>;
	pinctrl-4 = <&motor_dir_pin_gpio_high>;
	pinctrl-5 = <&motor_dir_pin_gpio_low>;
	pinctrl-6 = <&motor_dcen_pin_gpio_high>;
	pinctrl-7 = <&motor_dcen_pin_gpio_low>;
	pinctrl-8 = <&motor_timeout_pin_gpio_high>;
	pinctrl-9 = <&motor_timeout_pin_gpio_low>;
	vivo,motor-nenable = <&pio 176 0>;
	vivo,motor-nsleep = <&pio 17 0>;
	vivo,motor-dir = <&pio 175 0>;
	vivo,motor-dcen = <&pio 18 0>;
	vivo,motor-timeout = <&pio 170 0>;
	status = "okay";
};

&i2c5 {
	magnachip@0E {
		compatible = "magnachip,mxm1120,up";
		reg = <0x0E>;
		magachip,init-interval = <200>;
		vivo,id = <1>;
		status = "okay";
	};
	magnachip@0D {
		compatible = "magnachip,mxm1120,down";
		reg = <0x0D>;
		magachip,init-interval = <200>;
		vivo,id = <2>;
		status = "okay";
	};

	isentek@1A {
		compatible = "isentek,ist8801,up";
		reg = <0x1A>;
		magachip,init-interval = <200>;
		vivo,id = <1>;
		status = "okay";
	};
	isentek@19 {
		compatible = "isentek,ist8801,down";
		reg = <0x19>;
		magachip,init-interval = <200>;
		vivo,id = <2>;
		status = "okay";
	};
};
/* Add by vsen team [vivo vib camera] */

/* fengmingli add for usb start */
&usb3_tune {
	compatible = "mediatek,phy_tuning";
	u2_vrt_ref = <0x6>;
	u2_term_ref = <0x7>;
	u2_enhance = <0x2>;
	u2_vrt_ref_host = <0x3>;
	u2_term_ref_host = <0x3>;
	u2_enhance_host = <0x2>;
};
/* fengmingli add for usb end */
